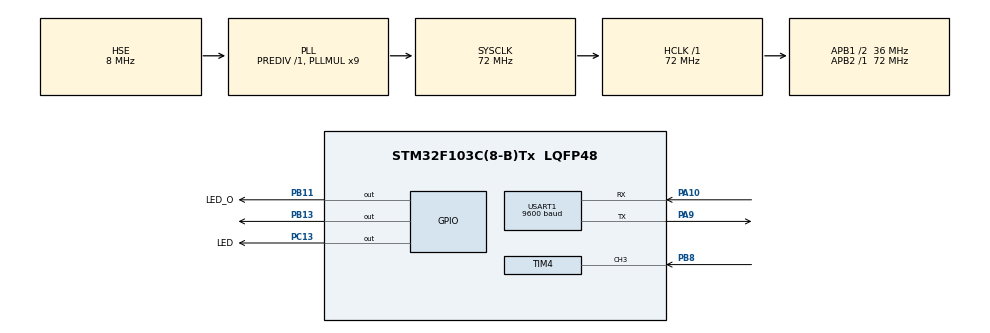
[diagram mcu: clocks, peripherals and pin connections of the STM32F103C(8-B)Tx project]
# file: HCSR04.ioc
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FREERTOS.Tasks01=Led,19,128,Led_Task,Default,NULL,Dynamic,NULL,NULL;distance,55,128,distance_get,Default,NULL,Dynamic,NULL,NULL
Mcu.Family=STM32F1
Mcu.Name=STM32F103C(8-B)Tx
Mcu.Package=LQFP48
NVIC.PriorityGroup=NVIC_PRIORITYGROUP_4
NVIC.TIM1_UP_IRQn=true\:15\:0\:false\:false\:true\:false\:false\:true\:true
NVIC.TIM4_IRQn=true\:5\:0\:false\:false\:true\:true\:true\:true\:true
NVIC.TimeBase=TIM1_UP_IRQn
NVIC.TimeBaseIP=TIM1
NVIC.USART1_IRQn=true\:5\:0\:false\:false\:true\:true\:true\:true\:true
PA10.Mode=Asynchronous
PA10.Signal=USART1_RX
PA13.Mode=Serial_Wire
PA13.Signal=SYS_JTMS-SWDIO
PA14.Mode=Serial_Wire
PA14.Signal=SYS_JTCK-SWCLK
PA9.Mode=Asynchronous
PA9.Signal=USART1_TX
PB11.GPIO_Label=LED_O
PB11.Signal=GPIO_Output
PB13.Signal=GPIO_Output
PB8.Signal=S_TIM4_CH3
PC13-TAMPER-RTC.GPIO_Label=LED
PC13-TAMPER-RTC.Signal=GPIO_Output
PD0-OSC_IN.Mode=HSE-External-Oscillator
PD0-OSC_IN.Signal=RCC_OSC_IN
PD1-OSC_OUT.Mode=HSE-External-Oscillator
PD1-OSC_OUT.Signal=RCC_OSC_OUT
ProjectManager.HeapSize=0x200
ProjectManager.StackSize=0x400
ProjectManager.TargetToolchain=STM32CubeIDE
RCC.AHBFreq_Value=72000000
RCC.APB1CLKDivider=RCC_HCLK_DIV2
RCC.APB1Freq_Value=36000000
RCC.APB1TimFreq_Value=72000000
RCC.APB2Freq_Value=72000000
RCC.APB2TimFreq_Value=72000000
RCC.HCLKFreq_Value=72000000
RCC.PLLMUL=RCC_PLL_MUL9
RCC.PLLSourceVirtual=RCC_PLLSOURCE_HSE
RCC.SYSCLKFreq_VALUE=72000000
RCC.SYSCLKSource=RCC_SYSCLKSOURCE_PLLCLK
RCC.USBFreq_Value=72000000
SH.S_TIM4_CH3.0=TIM4_CH3,Input_Capture3_from_TI3
TIM4.Channel-Input_Capture3_from_TI3=TIM_CHANNEL_3
TIM4.Prescaler=71
USART1.BaudRate=9600
USART1.VirtualMode=VM_ASYNC
VP_FREERTOS_VS_CMSIS_V2.Mode=CMSIS_V2
VP_SYS_VS_tim1.Mode=TIM1
VP_TIM4_VS_ClockSourceINT.Mode=Internal
board=custom

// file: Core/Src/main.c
/* USER CODE BEGIN Header */
/**
 ******************************************************************************
 * @file           : main.c
 * @brief          : Main program body
 ******************************************************************************
 * @attention
 *
 * Copyright (c) 2024 STMicroelectronics.
 * All rights reserved.
 *
 * This software is licensed under terms that can be found in the LICENSE file
 * in the root directory of this software component.
 * If no LICENSE file comes with this software, it is provided AS-IS.
 *
 ******************************************************************************
 */
/* USER CODE END Header */
#include "main.h"
#include "cmsis_os.h"
#include "tim.h"
#include "usart.h"
#include "gpio.h"

void SystemClock_Config(void);
void MX_FREERTOS_Init(void);

int main(void)
{

  /* MCU Configuration--------------------------------------------------------*/

  /* Reset of all peripherals, Initializes the Flash interface and the Systick. */
  HAL_Init();

  /* Configure the system clock */
  SystemClock_Config();

  /* Initialize all configured peripherals */
  MX_GPIO_Init();
  MX_USART1_UART_Init();
  MX_TIM4_Init();

  /* Init scheduler */
  osKernelInitialize();

  /* Call init function for freertos objects (in cmsis_os2.c) */
  MX_FREERTOS_Init();

  /* Start scheduler */
  osKernelStart();

  /* We should never get here as control is now taken by the scheduler */

  /* Infinite loop */
	while (1)
	{

	}
}

void SystemClock_Config(void)
{
  RCC_OscInitTypeDef RCC_OscInitStruct = {0};
  RCC_ClkInitTypeDef RCC_ClkInitStruct = {0};

  /** Initializes the RCC Oscillators according to the specified parameters
  * in the RCC_OscInitTypeDef structure.
  */
  RCC_OscInitStruct.OscillatorType = RCC_OSCILLATORTYPE_HSE;
  RCC_OscInitStruct.HSEState = RCC_HSE_ON;
  RCC_OscInitStruct.HSEPredivValue = RCC_HSE_PREDIV_DIV1;
  RCC_OscInitStruct.HSIState = RCC_HSI_ON;
  RCC_OscInitStruct.PLL.PLLState = RCC_PLL_ON;
  RCC_OscInitStruct.PLL.PLLSource = RCC_PLLSOURCE_HSE;
  RCC_OscInitStruct.PLL.PLLMUL = RCC_PLL_MUL9;
  if (HAL_RCC_OscConfig(&RCC_OscInitStruct) != HAL_OK)
  {
    Error_Handler();
  }

  /** Initializes the CPU, AHB and APB buses clocks
  */
  RCC_ClkInitStruct.ClockType = RCC_CLOCKTYPE_HCLK|RCC_CLOCKTYPE_SYSCLK
                              |RCC_CLOCKTYPE_PCLK1|RCC_CLOCKTYPE_PCLK2;
  RCC_ClkInitStruct.SYSCLKSource = RCC_SYSCLKSOURCE_PLLCLK;
  RCC_ClkInitStruct.AHBCLKDivider = RCC_SYSCLK_DIV1;
  RCC_ClkInitStruct.APB1CLKDivider = RCC_HCLK_DIV2;
  RCC_ClkInitStruct.APB2CLKDivider = RCC_HCLK_DIV1;

  if (HAL_RCC_ClockConfig(&RCC_ClkInitStruct, FLASH_LATENCY_2) != HAL_OK)
  {
    Error_Handler();
  }
}

void HAL_TIM_PeriodElapsedCallback(TIM_HandleTypeDef *htim)
{
  if (htim->Instance == TIM1) {
    HAL_IncTick();
  }
}

void Error_Handler(void)
{
	__disable_irq();
	while (1)
	{
	}
}

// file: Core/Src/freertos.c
/* USER CODE BEGIN Header */
/**
  ******************************************************************************
  * File Name          : freertos.c
  * Description        : Code for freertos applications
  ******************************************************************************
  * @attention
  *
  * Copyright (c) 2024 STMicroelectronics.
  * All rights reserved.
  *
  * This software is licensed under terms that can be found in the LICENSE file
  * in the root directory of this software component.
  * If no LICENSE file comes with this software, it is provided AS-IS.
  *
  ******************************************************************************
  */
/* USER CODE END Header */

#include "FreeRTOS.h"
#include "task.h"
#include "main.h"
#include "cmsis_os.h"

/* USER CODE BEGIN Includes */
#include"Ultrasonic.h"
#include "usart.h"
/* USER CODE END Includes */

/* Definitions for Led */
osThreadId_t LedHandle;
const osThreadAttr_t Led_attributes = {
  .name = "Led",
  .stack_size = 128 * 4,
  .priority = (osPriority_t) osPriorityBelowNormal3,
};
/* Definitions for distance */
osThreadId_t distanceHandle;
const osThreadAttr_t distance_attributes = {
  .name = "distance",
  .stack_size = 128 * 4,
  .priority = (osPriority_t) osPriorityRealtime7,
};

void Led_Task(void *argument);
void distance_get(void *argument);

void MX_FREERTOS_Init(void); /* (MISRA C 2004 rule 8.1) */

void MX_FREERTOS_Init(void) {

  /* Create the thread(s) */
  /* creation of Led */
  LedHandle = osThreadNew(Led_Task, NULL, &Led_attributes);

  /* creation of distance */
  distanceHandle = osThreadNew(distance_get, NULL, &distance_attributes);

}

void Led_Task(void *argument)
{
  /* USER CODE BEGIN Led_Task */
  /* Infinite loop */
  for(;;)
  {
    HAL_GPIO_TogglePin(LED_GPIO_Port,LED_Pin);
    HAL_UART_Transmit(&huart1,"Led_T",6,HAL_MAX_DELAY);
    osDelay(200);
  }
  /* USER CODE END Led_Task */
}

void distance_get(void *argument)
{
  /* USER CODE BEGIN distance_get */
  HCSR04_Init();
  uint8_t distance =0;
  /* Infinite loop */
  for(;;)
  {
    distance = Get_Distance();
    HAL_UART_Transmit(&huart1,&distance,1,10);
    if(distance > 5)
    {
      HAL_GPIO_WritePin(LED_O_GPIO_Port,LED_O_Pin,GPIO_PIN_RESET);
    }
    else{
      HAL_GPIO_WritePin(LED_O_GPIO_Port,LED_O_Pin,GPIO_PIN_SET);
    }

  }
  /* USER CODE END distance_get */
}
